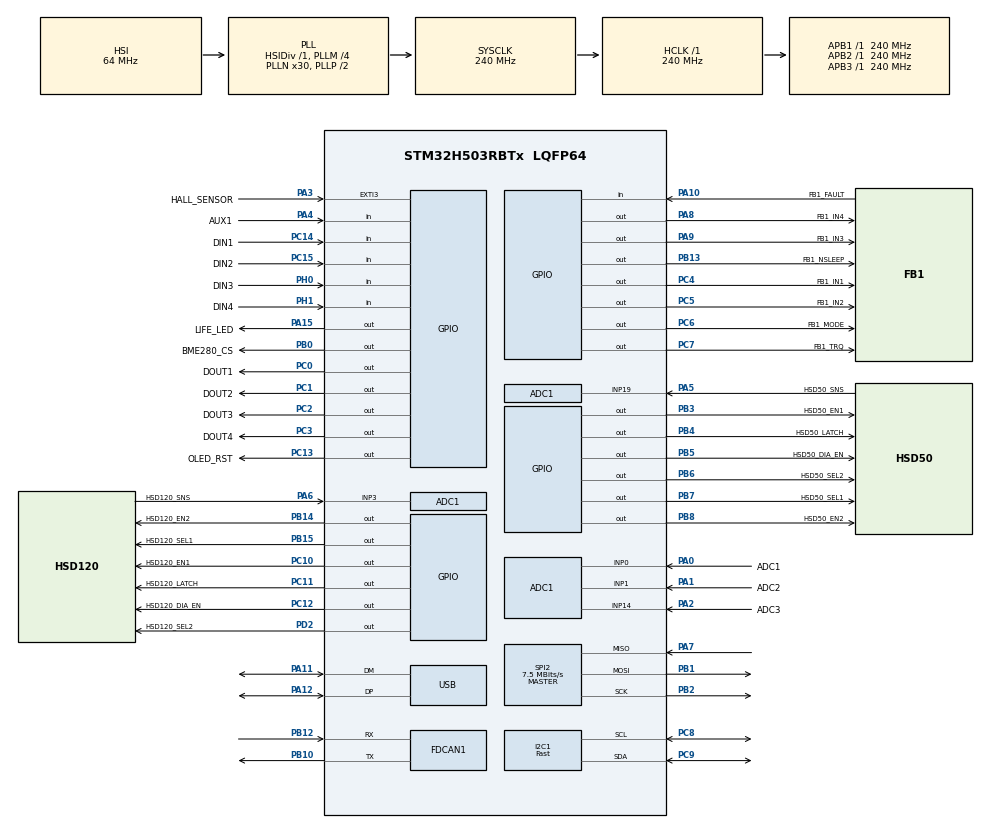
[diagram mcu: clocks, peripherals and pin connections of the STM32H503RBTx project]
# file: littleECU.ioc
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ADC1.Channel-0\#ChannelRegularConversion=ADC_CHANNEL_0
ADC1.ContinuousConvMode=ENABLE
ADC1.MonitoredBy-0\#ChannelRegularConversion=__NULL
ADC1.NbrOfConversionFlag=1
ADC1.OffsetNumber-0\#ChannelRegularConversion=ADC_OFFSET_NONE
ADC1.Rank-0\#ChannelRegularConversion=1
ADC1.SamplingTime-0\#ChannelRegularConversion=ADC_SAMPLETIME_2CYCLES_5
ADC1.master=1
BOOTPATH.BootPathName=LEGACY
BOOTPATH.UserSelectedBootPath=LEGACY
FDCAN1.AutoRetransmission=ENABLE
FDCAN1.CalculateBaudRateNominal=499999
FDCAN1.CalculateTimeBitNominal=2000
FDCAN1.CalculateTimeQuantumNominal=125.00000000000001
FDCAN1.ClockDivider=FDCAN_CLOCK_DIV2
FDCAN1.DataPrescaler=15
FDCAN1.DataSyncJumpWidth=3
FDCAN1.DataTimeSeg1=13
FDCAN1.DataTimeSeg2=2
FDCAN1.NominalPrescaler=15
FDCAN1.NominalSyncJumpWidth=3
FDCAN1.NominalTimeSeg1=13
FDCAN1.NominalTimeSeg2=2
FDCAN1.StdFiltersNbr=5
I2C1.I2C_Speed_Mode=I2C_Fast
I2C1.Timing=0x10B040DC
Mcu.Family=STM32H5
Mcu.Name=STM32H503RBTx
Mcu.Package=LQFP64
NVIC.EXTI3_IRQn=true\:0\:0\:false\:false\:true\:true\:true\:true
NVIC.FDCAN1_IT0_IRQn=true\:0\:0\:false\:false\:true\:true\:true\:true
NVIC.FDCAN1_IT1_IRQn=true\:0\:0\:false\:false\:true\:true\:true\:true
NVIC.PriorityGroup=NVIC_PRIORITYGROUP_4
NVIC.TIM2_IRQn=true\:0\:0\:false\:false\:true\:true\:true\:true
NVIC.TIM6_IRQn=true\:0\:0\:false\:false\:true\:true\:true\:true
NVIC.TIM7_IRQn=true\:0\:0\:false\:false\:true\:true\:true\:true
PA0.GPIO_Label=ADC1
PA0.Signal=ADCx_INP0
PA1.GPIO_Label=ADC2
PA1.Signal=ADCx_INP1
PA10.GPIO_Label=FB1_FAULT
PA10.Signal=GPIO_Input
PA11.Mode=Device
PA11.Signal=USB_DM
PA12.Mode=Device
PA12.Signal=USB_DP
PA13(JTMS/SWDIO).Signal=DEBUG_JTMS-SWDIO
PA14(JTCK/SWCLK).Signal=DEBUG_JTCK-SWCLK
PA15(JTDI).GPIO_Label=LIFE_LED
PA15(JTDI).Signal=GPIO_Output
PA2.GPIO_Label=ADC3
PA2.Signal=ADCx_INP14
PA3.GPIO_Label=HALL_SENSOR
PA3.GPIO_PuPd=GPIO_NOPULL
PA3.Signal=GPXTI3
PA4.GPIO_Label=AUX1
PA4.Signal=GPIO_Input
PA5.GPIO_Label=HSD50_SNS
PA5.Signal=ADCx_INP19
PA6.GPIO_Label=HSD120_SNS
PA6.Signal=ADCx_INP3
PA7.Mode=Full_Duplex_Master
PA7.Signal=SPI2_MISO
PA8.GPIO_Label=FB1_IN4
PA8.Signal=GPIO_Output
PA9.GPIO_Label=FB1_IN3
PA9.Signal=GPIO_Output
PB0.GPIO_Label=BME280_CS
PB0.Signal=GPIO_Output
PB1.Mode=Full_Duplex_Master
PB1.Signal=SPI2_MOSI
PB10.Mode=FDCAN_Activate
PB10.Signal=FDCAN1_TX
PB12.Mode=FDCAN_Activate
PB12.Signal=FDCAN1_RX
PB13.GPIO_Label=FB1_NSLEEP
PB13.Signal=GPIO_Output
PB14.GPIO_Label=HSD120_EN2
PB14.Signal=GPIO_Output
PB15.GPIO_Label=HSD120_SEL1
PB15.Signal=GPIO_Output
PB2.Mode=Full_Duplex_Master
PB2.Signal=SPI2_SCK
PB3(JTDO/TRACESWO).GPIO_Label=HSD50_EN1
PB3(JTDO/TRACESWO).Signal=GPIO_Output
PB4(NJTRST).GPIO_Label=HSD50_LATCH
PB4(NJTRST).Signal=GPIO_Output
PB5.GPIO_Label=HSD50_DIA_EN
PB5.Signal=GPIO_Output
PB6.GPIO_Label=HSD50_SEL2
PB6.Signal=GPIO_Output
PB7.GPIO_Label=HSD50_SEL1
PB7.Signal=GPIO_Output
PB8.GPIO_Label=HSD50_EN2
PB8.Signal=GPIO_Output
PC0.GPIO_Label=DOUT1
PC0.Signal=GPIO_Output
PC1.GPIO_Label=DOUT2
PC1.Signal=GPIO_Output
PC10.GPIO_Label=HSD120_EN1
PC10.Signal=GPIO_Output
PC11.GPIO_Label=HSD120_LATCH
PC11.Signal=GPIO_Output
PC12.GPIO_Label=HSD120_DIA_EN
PC12.Signal=GPIO_Output
PC13.GPIO_Label=OLED_RST
PC13.Signal=GPIO_Output
PC14-OSC32_IN(OSC32_IN).GPIO_Label=DIN1
PC14-OSC32_IN(OSC32_IN).GPIO_PuPd=GPIO_NOPULL
PC14-OSC32_IN(OSC32_IN).Signal=GPIO_Input
PC15-OSC32_OUT(OSC32_OUT).GPIO_Label=DIN2
PC15-OSC32_OUT(OSC32_OUT).GPIO_PuPd=GPIO_NOPULL
PC15-OSC32_OUT(OSC32_OUT).Signal=GPIO_Input
PC2.GPIO_Label=DOUT3
PC2.Signal=GPIO_Output
PC3.GPIO_Label=DOUT4
PC3.Signal=GPIO_Output
PC4.GPIO_Label=FB1_IN1
PC4.Signal=GPIO_Output
PC5.GPIO_Label=FB1_IN2
PC5.Signal=GPIO_Output
PC6.GPIO_Label=FB1_MODE
PC6.Signal=GPIO_Output
PC7.GPIO_Label=FB1_TRQ
PC7.Signal=GPIO_Output
PC8.Mode=I2C
PC8.Signal=I2C1_SCL
PC9.Mode=I2C
PC9.Signal=I2C1_SDA
PD2.GPIO_Label=HSD120_SEL2
PD2.Signal=GPIO_Output
PH0-OSC_IN(PH0).GPIO_Label=DIN3
PH0-OSC_IN(PH0).GPIO_PuPd=GPIO_NOPULL
PH0-OSC_IN(PH0).Signal=GPIO_Input
PH1-OSC_OUT(PH1).GPIO_Label=DIN4
PH1-OSC_OUT(PH1).Signal=GPIO_Input
ProjectManager.HeapSize=0x200
ProjectManager.StackSize=0x400
ProjectManager.TargetToolchain=CMake
RCC.ADCCLockSelection=RCC_ADCDACCLKSOURCE_PLL2R
RCC.ADCFreq_Value=120000000
RCC.AHBFreq_Value=240000000
RCC.APB1Freq_Value=240000000
RCC.APB1TimFreq_Value=240000000
RCC.APB2Freq_Value=240000000
RCC.APB2TimFreq_Value=240000000
RCC.APB3Freq_Value=240000000
RCC.CSI_VALUE=4000000
RCC.CortexFreq_Value=240000000
RCC.EPOD_VALUE=64000000
RCC.FDCANClockSelection=RCC_FDCANCLKSOURCE_PLL1Q
RCC.HCLKFreq_Value=240000000
RCC.HSE_VALUE=25000000
RCC.HSI48_VALUE=48000000
RCC.HSIDiv=RCC_HSI_DIV1
RCC.HSI_VALUE=64000000
RCC.LSE_VALUE=32768
RCC.LSIRC_VALUE=32000
RCC.PLL2N=120
RCC.PLL2R=4
RCC.PLLFRACN=0
RCC.PLLM=4
RCC.PLLN=30
RCC.PLLSourceVirtual=RCC_PLL1_SOURCE_HSI
RCC.SYSCLKFreq_VALUE=240000000
RCC.SYSCLKSource=RCC_SYSCLKSOURCE_PLLCLK
RCC.USBFreq_Value=48000000
RCC.VCOOutputFreq_Value=480000000
SH.ADCx_INP0.0=ADC1_INP0,IN0-Single-Ended
SH.ADCx_INP1.0=ADC1_INP1,IN1-Single-Ended
SH.ADCx_INP14.0=ADC1_INP14,IN14-Single-Ended
SH.ADCx_INP19.0=ADC1_INP19,IN19-Single-Ended
SH.ADCx_INP3.0=ADC1_INP3,IN3-Single-Ended
SPI2.BaudRatePrescaler=SPI_BAUDRATEPRESCALER_32
SPI2.CLKPhase=SPI_PHASE_2EDGE
SPI2.CLKPolarity=SPI_POLARITY_HIGH
SPI2.CalculateBaudRate=7.5 MBits/s
SPI2.DataSize=SPI_DATASIZE_8BIT
SPI2.Direction=SPI_DIRECTION_2LINES
SPI2.Mode=SPI_MODE_MASTER
SPI2.VirtualType=VM_MASTER
TIM2.Prescaler=23
TIM6.PeriodNoDither=100
TIM6.Prescaler=23
TIM7.PeriodNoDither=65535
TIM7.Prescaler=479
USB.Sof_enable-Device=ENABLE
USB.VirtualMode=Device_Only
VP_BOOTPATH_VS_BOOTPATH.Mode=BP_Activate
VP_CORTEX_M33_NS_VS_Hclk.Mode=Hclk_Mode
VP_ICACHE_VS_ICACHE.Mode=DirectMappedCache
VP_MEMORYMAP_VS_MEMORYMAP.Mode=CurAppReg
VP_PWR_VS_DBSignals.Mode=DisableDeadBatterySignals
VP_PWR_VS_LPOM.Mode=PowerOptimisation
VP_PWR_VS_SECSignals.Mode=Security/Privilege
VP_TIM2_VS_ClockSourceINT.Mode=Internal
VP_TIM6_VS_ClockSourceINT.Mode=Enable_Timer
VP_TIM7_VS_ClockSourceINT.Mode=Enable_Timer
board=custom

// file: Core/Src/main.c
/* USER CODE BEGIN Header */
/**
  ******************************************************************************
  * @file           : main.c
  * @brief          : Main program body
  ******************************************************************************
  * @attention
  *
  * Copyright (c) 2025 STMicroelectronics.
  * All rights reserved.
  *
  * This software is licensed under terms that can be found in the LICENSE file
  * in the root directory of this software component.
  * If no LICENSE file comes with this software, it is provided AS-IS.
  *
  ******************************************************************************
  */
/* USER CODE END Header */
#include "main.h"

/* USER CODE BEGIN Includes */
#include "core.h"
#include "timing.h"

/* USER CODE END Includes */

ADC_HandleTypeDef hadc1;

FDCAN_HandleTypeDef hfdcan1;

I2C_HandleTypeDef hi2c1;

SPI_HandleTypeDef hspi2;

TIM_HandleTypeDef htim2;
TIM_HandleTypeDef htim6;
TIM_HandleTypeDef htim7;

PCD_HandleTypeDef hpcd_USB_DRD_FS;

void SystemClock_Config(void);
static void MX_GPIO_Init(void);
static void MX_ADC1_Init(void);
static void MX_FDCAN1_Init(void);
static void MX_I2C1_Init(void);
static void MX_SPI2_Init(void);
static void MX_TIM2_Init(void);
static void MX_TIM6_Init(void);
static void MX_TIM7_Init(void);
static void MX_USB_PCD_Init(void);
static void MX_ICACHE_Init(void);

int main(void)
{

  /* MCU Configuration--------------------------------------------------------*/

  /* Reset of all peripherals, Initializes the Flash interface and the Systick. */
  HAL_Init();

  /* Configure the system clock */
  SystemClock_Config();

  /* Initialize all configured peripherals */
  MX_GPIO_Init();
  MX_ADC1_Init();
  MX_FDCAN1_Init();
  MX_I2C1_Init();
  MX_SPI2_Init();
  MX_TIM2_Init();
  MX_TIM6_Init();
  MX_TIM7_Init();
  MX_USB_PCD_Init();
  MX_ICACHE_Init();
  /* USER CODE BEGIN 2 */

  core_init(&htim6, &htim2, &htim7, &hfdcan1);

  /* USER CODE END 2 */

  /* Infinite loop */
  /* USER CODE BEGIN WHILE */
  while (1)
  {
    HAL_Delay(60);
    // simulate tdc callback
    // timing_tdc_callback();
    /* USER CODE END WHILE */

  }
}

void SystemClock_Config(void)
{
  RCC_OscInitTypeDef RCC_OscInitStruct = {0};
  RCC_ClkInitTypeDef RCC_ClkInitStruct = {0};

  /** Configure the main internal regulator output voltage
  */
  __HAL_PWR_VOLTAGESCALING_CONFIG(PWR_REGULATOR_VOLTAGE_SCALE0);

  while(!__HAL_PWR_GET_FLAG(PWR_FLAG_VOSRDY)) {}

  /** Initializes the RCC Oscillators according to the specified parameters
  * in the RCC_OscInitTypeDef structure.
  */
  RCC_OscInitStruct.OscillatorType = RCC_OSCILLATORTYPE_HSI48|RCC_OSCILLATORTYPE_HSI
                              |RCC_OSCILLATORTYPE_CSI;
  RCC_OscInitStruct.HSIState = RCC_HSI_ON;
  RCC_OscInitStruct.HSIDiv = RCC_HSI_DIV1;
  RCC_OscInitStruct.HSICalibrationValue = RCC_HSICALIBRATION_DEFAULT;
  RCC_OscInitStruct.HSI48State = RCC_HSI48_ON;
  RCC_OscInitStruct.CSIState = RCC_CSI_ON;
  RCC_OscInitStruct.CSICalibrationValue = RCC_CSICALIBRATION_DEFAULT;
  RCC_OscInitStruct.PLL.PLLState = RCC_PLL_ON;
  RCC_OscInitStruct.PLL.PLLSource = RCC_PLL1_SOURCE_HSI;
  RCC_OscInitStruct.PLL.PLLM = 4;
  RCC_OscInitStruct.PLL.PLLN = 30;
  RCC_OscInitStruct.PLL.PLLP = 2;
  RCC_OscInitStruct.PLL.PLLQ = 2;
  RCC_OscInitStruct.PLL.PLLR = 2;
  RCC_OscInitStruct.PLL.PLLRGE = RCC_PLL1_VCIRANGE_3;
  RCC_OscInitStruct.PLL.PLLVCOSEL = RCC_PLL1_VCORANGE_WIDE;
  RCC_OscInitStruct.PLL.PLLFRACN = 0;
  if (HAL_RCC_OscConfig(&RCC_OscInitStruct) != HAL_OK)
  {
    Error_Handler();
  }

  /** Initializes the CPU, AHB and APB buses clocks
  */
  RCC_ClkInitStruct.ClockType = RCC_CLOCKTYPE_HCLK|RCC_CLOCKTYPE_SYSCLK
                              |RCC_CLOCKTYPE_PCLK1|RCC_CLOCKTYPE_PCLK2
                              |RCC_CLOCKTYPE_PCLK3;
  RCC_ClkInitStruct.SYSCLKSource = RCC_SYSCLKSOURCE_PLLCLK;
  RCC_ClkInitStruct.AHBCLKDivider = RCC_SYSCLK_DIV1;
  RCC_ClkInitStruct.APB1CLKDivider = RCC_HCLK_DIV1;
  RCC_ClkInitStruct.APB2CLKDivider = RCC_HCLK_DIV1;
  RCC_ClkInitStruct.APB3CLKDivider = RCC_HCLK_DIV1;

  if (HAL_RCC_ClockConfig(&RCC_ClkInitStruct, FLASH_LATENCY_5) != HAL_OK)
  {
    Error_Handler();
  }
}

static void MX_ADC1_Init(void)
{

  ADC_ChannelConfTypeDef sConfig = {0};

  /** Common config
  */
  hadc1.Instance = ADC1;
  hadc1.Init.ClockPrescaler = ADC_CLOCK_ASYNC_DIV4;
  hadc1.Init.Resolution = ADC_RESOLUTION_12B;
  hadc1.Init.DataAlign = ADC_DATAALIGN_RIGHT;
  hadc1.Init.ScanConvMode = ADC_SCAN_DISABLE;
  hadc1.Init.EOCSelection = ADC_EOC_SINGLE_CONV;
  hadc1.Init.LowPowerAutoWait = DISABLE;
  hadc1.Init.ContinuousConvMode = ENABLE;
  hadc1.Init.NbrOfConversion = 1;
  hadc1.Init.DiscontinuousConvMode = DISABLE;
  hadc1.Init.ExternalTrigConv = ADC_SOFTWARE_START;
  hadc1.Init.ExternalTrigConvEdge = ADC_EXTERNALTRIGCONVEDGE_NONE;
  hadc1.Init.DMAContinuousRequests = DISABLE;
  hadc1.Init.SamplingMode = ADC_SAMPLING_MODE_NORMAL;
  hadc1.Init.Overrun = ADC_OVR_DATA_PRESERVED;
  hadc1.Init.OversamplingMode = DISABLE;
  if (HAL_ADC_Init(&hadc1) != HAL_OK)
  {
    Error_Handler();
  }

  /** Configure Regular Channel
  */
  sConfig.Channel = ADC_CHANNEL_0;
  sConfig.Rank = ADC_REGULAR_RANK_1;
  sConfig.SamplingTime = ADC_SAMPLETIME_2CYCLES_5;
  sConfig.SingleDiff = ADC_SINGLE_ENDED;
  sConfig.OffsetNumber = ADC_OFFSET_NONE;
  sConfig.Offset = 0;
  if (HAL_ADC_ConfigChannel(&hadc1, &sConfig) != HAL_OK)
  {
    Error_Handler();
  }

}

static void MX_FDCAN1_Init(void)
{

  hfdcan1.Instance = FDCAN1;
  hfdcan1.Init.ClockDivider = FDCAN_CLOCK_DIV2;
  hfdcan1.Init.FrameFormat = FDCAN_FRAME_CLASSIC;
  hfdcan1.Init.Mode = FDCAN_MODE_NORMAL;
  hfdcan1.Init.AutoRetransmission = DISABLE;
  hfdcan1.Init.TransmitPause = DISABLE;
  hfdcan1.Init.ProtocolException = DISABLE;
  hfdcan1.Init.NominalPrescaler = 15;
  hfdcan1.Init.NominalSyncJumpWidth = 3;
  hfdcan1.Init.NominalTimeSeg1 = 13;
  hfdcan1.Init.NominalTimeSeg2 = 2;
  hfdcan1.Init.DataPrescaler = 15;
  hfdcan1.Init.DataSyncJumpWidth = 3;
  hfdcan1.Init.DataTimeSeg1 = 13;
  hfdcan1.Init.DataTimeSeg2 = 2;
  hfdcan1.Init.StdFiltersNbr = 5;
  hfdcan1.Init.ExtFiltersNbr = 0;
  hfdcan1.Init.TxFifoQueueMode = FDCAN_TX_FIFO_OPERATION;
  if (HAL_FDCAN_Init(&hfdcan1) != HAL_OK)
  {
    Error_Handler();
  }

}

static void MX_I2C1_Init(void)
{

  hi2c1.Instance = I2C1;
  hi2c1.Init.Timing = 0x10B040DC;
  hi2c1.Init.OwnAddress1 = 0;
  hi2c1.Init.AddressingMode = I2C_ADDRESSINGMODE_7BIT;
  hi2c1.Init.DualAddressMode = I2C_DUALADDRESS_DISABLE;
  hi2c1.Init.OwnAddress2 = 0;
  hi2c1.Init.OwnAddress2Masks = I2C_OA2_NOMASK;
  hi2c1.Init.GeneralCallMode = I2C_GENERALCALL_DISABLE;
  hi2c1.Init.NoStretchMode = I2C_NOSTRETCH_DISABLE;
  if (HAL_I2C_Init(&hi2c1) != HAL_OK)
  {
    Error_Handler();
  }

  /** Configure Analogue filter
  */
  if (HAL_I2CEx_ConfigAnalogFilter(&hi2c1, I2C_ANALOGFILTER_ENABLE) != HAL_OK)
  {
    Error_Handler();
  }

  /** Configure Digital filter
  */
  if (HAL_I2CEx_ConfigDigitalFilter(&hi2c1, 0) != HAL_OK)
  {
    Error_Handler();
  }

}

static void MX_ICACHE_Init(void)
{

  /** Enable instruction cache in 1-way (direct mapped cache)
  */
  if (HAL_ICACHE_ConfigAssociativityMode(ICACHE_1WAY) != HAL_OK)
  {
    Error_Handler();
  }
  if (HAL_ICACHE_Enable() != HAL_OK)
  {
    Error_Handler();
  }

}

static void MX_SPI2_Init(void)
{

  /* SPI2 parameter configuration*/
  hspi2.Instance = SPI2;
  hspi2.Init.Mode = SPI_MODE_MASTER;
  hspi2.Init.Direction = SPI_DIRECTION_2LINES;
  hspi2.Init.DataSize = SPI_DATASIZE_8BIT;
  hspi2.Init.CLKPolarity = SPI_POLARITY_HIGH;
  hspi2.Init.CLKPhase = SPI_PHASE_2EDGE;
  hspi2.Init.NSS = SPI_NSS_SOFT;
  hspi2.Init.BaudRatePrescaler = SPI_BAUDRATEPRESCALER_32;
  hspi2.Init.FirstBit = SPI_FIRSTBIT_MSB;
  hspi2.Init.TIMode = SPI_TIMODE_DISABLE;
  hspi2.Init.CRCCalculation = SPI_CRCCALCULATION_DISABLE;
  hspi2.Init.CRCPolynomial = 0x7;
  hspi2.Init.NSSPMode = SPI_NSS_PULSE_DISABLE;
  hspi2.Init.NSSPolarity = SPI_NSS_POLARITY_LOW;
  hspi2.Init.FifoThreshold = SPI_FIFO_THRESHOLD_01DATA;
  hspi2.Init.MasterSSIdleness = SPI_MASTER_SS_IDLENESS_00CYCLE;
  hspi2.Init.MasterInterDataIdleness = SPI_MASTER_INTERDATA_IDLENESS_00CYCLE;
  hspi2.Init.MasterReceiverAutoSusp = SPI_MASTER_RX_AUTOSUSP_DISABLE;
  hspi2.Init.MasterKeepIOState = SPI_MASTER_KEEP_IO_STATE_DISABLE;
  hspi2.Init.IOSwap = SPI_IO_SWAP_DISABLE;
  hspi2.Init.ReadyMasterManagement = SPI_RDY_MASTER_MANAGEMENT_INTERNALLY;
  hspi2.Init.ReadyPolarity = SPI_RDY_POLARITY_HIGH;
  if (HAL_SPI_Init(&hspi2) != HAL_OK)
  {
    Error_Handler();
  }

}

static void MX_TIM2_Init(void)
{

  TIM_ClockConfigTypeDef sClockSourceConfig = {0};
  TIM_MasterConfigTypeDef sMasterConfig = {0};

  htim2.Instance = TIM2;
  htim2.Init.Prescaler = 23;
  htim2.Init.CounterMode = TIM_COUNTERMODE_UP;
  htim2.Init.Period = 4294967295;
  htim2.Init.ClockDivision = TIM_CLOCKDIVISION_DIV1;
  htim2.Init.AutoReloadPreload = TIM_AUTORELOAD_PRELOAD_DISABLE;
  if (HAL_TIM_Base_Init(&htim2) != HAL_OK)
  {
    Error_Handler();
  }
  sClockSourceConfig.ClockSource = TIM_CLOCKSOURCE_INTERNAL;
  if (HAL_TIM_ConfigClockSource(&htim2, &sClockSourceConfig) != HAL_OK)
  {
    Error_Handler();
  }
  sMasterConfig.MasterOutputTrigger = TIM_TRGO_RESET;
  sMasterConfig.MasterSlaveMode = TIM_MASTERSLAVEMODE_DISABLE;
  if (HAL_TIMEx_MasterConfigSynchronization(&htim2, &sMasterConfig) != HAL_OK)
  {
    Error_Handler();
  }

}

static void MX_TIM6_Init(void)
{

  TIM_MasterConfigTypeDef sMasterConfig = {0};

  htim6.Instance = TIM6;
  htim6.Init.Prescaler = 23;
  htim6.Init.CounterMode = TIM_COUNTERMODE_UP;
  htim6.Init.Period = 100;
  htim6.Init.AutoReloadPreload = TIM_AUTORELOAD_PRELOAD_DISABLE;
  if (HAL_TIM_Base_Init(&htim6) != HAL_OK)
  {
    Error_Handler();
  }
  sMasterConfig.MasterOutputTrigger = TIM_TRGO_RESET;
  sMasterConfig.MasterSlaveMode = TIM_MASTERSLAVEMODE_DISABLE;
  if (HAL_TIMEx_MasterConfigSynchronization(&htim6, &sMasterConfig) != HAL_OK)
  {
    Error_Handler();
  }

}

static void MX_TIM7_Init(void)
{

  TIM_MasterConfigTypeDef sMasterConfig = {0};

  htim7.Instance = TIM7;
  htim7.Init.Prescaler = 479;
  htim7.Init.CounterMode = TIM_COUNTERMODE_UP;
  htim7.Init.Period = 65535;
  htim7.Init.AutoReloadPreload = TIM_AUTORELOAD_PRELOAD_DISABLE;
  if (HAL_TIM_Base_Init(&htim7) != HAL_OK)
  {
    Error_Handler();
  }
  sMasterConfig.MasterOutputTrigger = TIM_TRGO_RESET;
  sMasterConfig.MasterSlaveMode = TIM_MASTERSLAVEMODE_DISABLE;
  if (HAL_TIMEx_MasterConfigSynchronization(&htim7, &sMasterConfig) != HAL_OK)
  {
    Error_Handler();
  }

}

static void MX_USB_PCD_Init(void)
{

  hpcd_USB_DRD_FS.Instance = USB_DRD_FS;
  hpcd_USB_DRD_FS.Init.dev_endpoints = 8;
  hpcd_USB_DRD_FS.Init.speed = USBD_FS_SPEED;
  hpcd_USB_DRD_FS.Init.phy_itface = PCD_PHY_EMBEDDED;
  hpcd_USB_DRD_FS.Init.Sof_enable = ENABLE;
  hpcd_USB_DRD_FS.Init.low_power_enable = DISABLE;
  hpcd_USB_DRD_FS.Init.lpm_enable = DISABLE;
  hpcd_USB_DRD_FS.Init.battery_charging_enable = DISABLE;
  hpcd_USB_DRD_FS.Init.vbus_sensing_enable = DISABLE;
  hpcd_USB_DRD_FS.Init.bulk_doublebuffer_enable = DISABLE;
  hpcd_USB_DRD_FS.Init.iso_singlebuffer_enable = DISABLE;
  if (HAL_PCD_Init(&hpcd_USB_DRD_FS) != HAL_OK)
  {
    Error_Handler();
  }

}

static void MX_GPIO_Init(void)
{
  GPIO_InitTypeDef GPIO_InitStruct = {0};

  /* GPIO Ports Clock Enable */
  __HAL_RCC_GPIOC_CLK_ENABLE();
  __HAL_RCC_GPIOH_CLK_ENABLE();
  __HAL_RCC_GPIOA_CLK_ENABLE();
  __HAL_RCC_GPIOB_CLK_ENABLE();
  __HAL_RCC_GPIOD_CLK_ENABLE();

  /*Configure GPIO pin Output Level */
  HAL_GPIO_WritePin(GPIOC, OLED_RST_Pin|DOUT1_Pin|DOUT2_Pin|DOUT3_Pin
                          |DOUT4_Pin|FB1_IN1_Pin|FB1_IN2_Pin|FB1_MODE_Pin
                          |FB1_TRQ_Pin|HSD120_EN1_Pin|HSD120_LATCH_Pin|HSD120_DIA_EN_Pin, GPIO_PIN_RESET);

  /*Configure GPIO pin Output Level */
  HAL_GPIO_WritePin(GPIOB, BME280_CS_Pin|FB1_NSLEEP_Pin|HSD120_EN2_Pin|HSD120_SEL1_Pin
                          |HSD50_EN1_Pin|HSD50_LATCH_Pin|HSD50_DIA_EN_Pin|HSD50_SEL2_Pin
                          |HSD50_SEL1_Pin|HSD50_EN2_Pin, GPIO_PIN_RESET);

  /*Configure GPIO pin Output Level */
  HAL_GPIO_WritePin(GPIOA, FB1_IN4_Pin|FB1_IN3_Pin|LIFE_LED_Pin, GPIO_PIN_RESET);

  /*Configure GPIO pin Output Level */
  HAL_GPIO_WritePin(HSD120_SEL2_GPIO_Port, HSD120_SEL2_Pin, GPIO_PIN_RESET);

  /*Configure GPIO pins : OLED_RST_Pin DOUT1_Pin DOUT2_Pin DOUT3_Pin
                           DOUT4_Pin FB1_IN1_Pin FB1_IN2_Pin FB1_MODE_Pin
                           FB1_TRQ_Pin HSD120_EN1_Pin HSD120_LATCH_Pin HSD120_DIA_EN_Pin */
  GPIO_InitStruct.Pin = OLED_RST_Pin|DOUT1_Pin|DOUT2_Pin|DOUT3_Pin
                          |DOUT4_Pin|FB1_IN1_Pin|FB1_IN2_Pin|FB1_MODE_Pin
                          |FB1_TRQ_Pin|HSD120_EN1_Pin|HSD120_LATCH_Pin|HSD120_DIA_EN_Pin;
  GPIO_InitStruct.Mode = GPIO_MODE_OUTPUT_PP;
  GPIO_InitStruct.Pull = GPIO_NOPULL;
  GPIO_InitStruct.Speed = GPIO_SPEED_FREQ_LOW;
  HAL_GPIO_Init(GPIOC, &GPIO_InitStruct);

  /*Configure GPIO pins : DIN1_Pin DIN2_Pin */
  GPIO_InitStruct.Pin = DIN1_Pin|DIN2_Pin;
  GPIO_InitStruct.Mode = GPIO_MODE_INPUT;
  GPIO_InitStruct.Pull = GPIO_NOPULL;
  HAL_GPIO_Init(GPIOC, &GPIO_InitStruct);

  /*Configure GPIO pins : DIN3_Pin DIN4_Pin */
  GPIO_InitStruct.Pin = DIN3_Pin|DIN4_Pin;
  GPIO_InitStruct.Mode = GPIO_MODE_INPUT;
  GPIO_InitStruct.Pull = GPIO_NOPULL;
  HAL_GPIO_Init(GPIOH, &GPIO_InitStruct);

  /*Configure GPIO pin : HALL_SENSOR_Pin */
  GPIO_InitStruct.Pin = HALL_SENSOR_Pin;
  GPIO_InitStruct.Mode = GPIO_MODE_IT_RISING;
  GPIO_InitStruct.Pull = GPIO_NOPULL;
  HAL_GPIO_Init(HALL_SENSOR_GPIO_Port, &GPIO_InitStruct);

  /*Configure GPIO pins : AUX1_Pin FB1_FAULT_Pin */
  GPIO_InitStruct.Pin = AUX1_Pin|FB1_FAULT_Pin;
  GPIO_InitStruct.Mode = GPIO_MODE_INPUT;
  GPIO_InitStruct.Pull = GPIO_NOPULL;
  HAL_GPIO_Init(GPIOA, &GPIO_InitStruct);

  /*Configure GPIO pins : BME280_CS_Pin FB1_NSLEEP_Pin HSD120_EN2_Pin HSD120_SEL1_Pin
                           HSD50_EN1_Pin HSD50_LATCH_Pin HSD50_DIA_EN_Pin HSD50_SEL2_Pin
                           HSD50_SEL1_Pin HSD50_EN2_Pin */
  GPIO_InitStruct.Pin = BME280_CS_Pin|FB1_NSLEEP_Pin|HSD120_EN2_Pin|HSD120_SEL1_Pin
                          |HSD50_EN1_Pin|HSD50_LATCH_Pin|HSD50_DIA_EN_Pin|HSD50_SEL2_Pin
                          |HSD50_SEL1_Pin|HSD50_EN2_Pin;
  GPIO_InitStruct.Mode = GPIO_MODE_OUTPUT_PP;
  GPIO_InitStruct.Pull = GPIO_NOPULL;
  GPIO_InitStruct.Speed = GPIO_SPEED_FREQ_LOW;
  HAL_GPIO_Init(GPIOB, &GPIO_InitStruct);

  /*Configure GPIO pins : FB1_IN4_Pin FB1_IN3_Pin LIFE_LED_Pin */
  GPIO_InitStruct.Pin = FB1_IN4_Pin|FB1_IN3_Pin|LIFE_LED_Pin;
  GPIO_InitStruct.Mode = GPIO_MODE_OUTPUT_PP;
  GPIO_InitStruct.Pull = GPIO_NOPULL;
  GPIO_InitStruct.Speed = GPIO_SPEED_FREQ_LOW;
  HAL_GPIO_Init(GPIOA, &GPIO_InitStruct);

  /*Configure GPIO pin : HSD120_SEL2_Pin */
  GPIO_InitStruct.Pin = HSD120_SEL2_Pin;
  GPIO_InitStruct.Mode = GPIO_MODE_OUTPUT_PP;
  GPIO_InitStruct.Pull = GPIO_NOPULL;
  GPIO_InitStruct.Speed = GPIO_SPEED_FREQ_LOW;
  HAL_GPIO_Init(HSD120_SEL2_GPIO_Port, &GPIO_InitStruct);

  /* EXTI interrupt init*/
  HAL_NVIC_SetPriority(EXTI3_IRQn, 0, 0);
  HAL_NVIC_EnableIRQ(EXTI3_IRQn);

}

void Error_Handler(void)
{
  __disable_irq();
  while (1)
  {
  }
}
